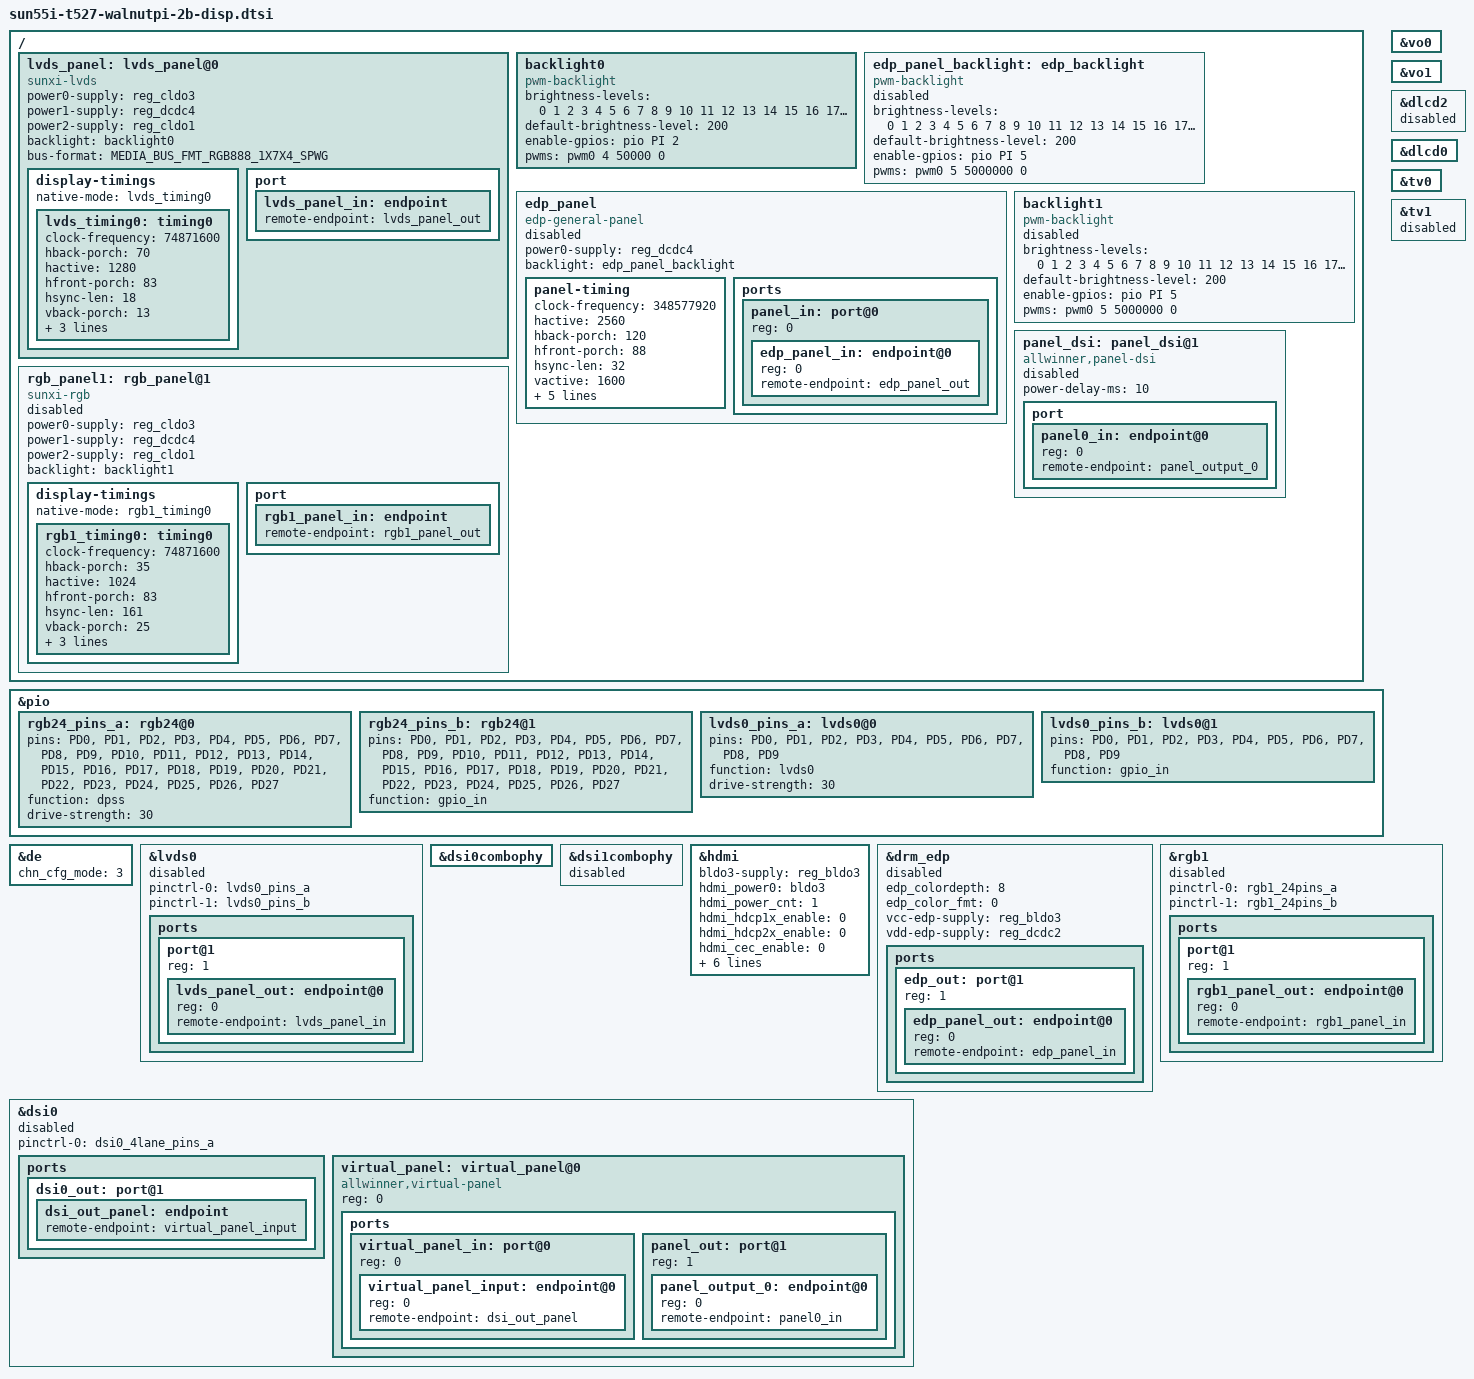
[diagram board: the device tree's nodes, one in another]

&pio {
	
	rgb24_pins_a: rgb24@0 {
		pins = "PD0", "PD1", "PD2", "PD3", "PD4", "PD5", "PD6", "PD7", "PD8", "PD9", \
		"PD10", "PD11", "PD12", "PD13", "PD14", "PD15", "PD16", "PD17", "PD18", "PD19", \
		"PD20", "PD21", "PD22","PD23","PD24","PD25","PD26","PD27";
		function = "dpss";
		drive-strength = <30>;
	};
	
	rgb24_pins_b: rgb24@1 {
		pins = "PD0", "PD1", "PD2", "PD3", "PD4", "PD5", "PD6", "PD7", "PD8", "PD9", \
		"PD10", "PD11", "PD12", "PD13", "PD14", "PD15", "PD16", "PD17", "PD18", "PD19", \
		"PD20", "PD21", "PD22", "PD23","PD24","PD25","PD26","PD27";
		function = "gpio_in";
	};
	
	lvds0_pins_a: lvds0@0 {
		pins = "PD0", "PD1", "PD2", "PD3", "PD4", "PD5", "PD6", "PD7", "PD8", "PD9";
		function = "lvds0";
		drive-strength = <30>;
	};
	
	lvds0_pins_b: lvds0@1 {
		pins = "PD0", "PD1", "PD2", "PD3", "PD4", "PD5", "PD6", "PD7", "PD8", "PD9";
		function = "gpio_in";
	};
};


&de {
	chn_cfg_mode = <3>;
	status = "okay";
};

&vo0 {
	status = "okay";
};

&vo1 {
	status = "okay";
};



&dlcd2 {
	status = "disabled";
};


/ {
	lvds_panel: lvds_panel@0 {
		compatible = "sunxi-lvds";
		status = "okay";
		power0-supply = <&reg_cldo3>;
		power1-supply = <&reg_dcdc4>;
		power2-supply = <&reg_cldo1>;
		backlight = <&backlight0>;
		bus-format = <MEDIA_BUS_FMT_RGB888_1X7X4_SPWG>;
		display-timings {
			native-mode = <&lvds_timing0>;
			lvds_timing0: timing0 {
				clock-frequency = <74871600>;
				hback-porch = <70>;
				hactive = <1280>;
				hfront-porch = <83>;
				hsync-len = <18>;
				vback-porch = <13>;
				vactive = <800>;
				vfront-porch = <37>;
				vsync-len = <10>;
			};
		};
		port {
			lvds_panel_in: endpoint {
				remote-endpoint = <&lvds_panel_out>;
			};
		};
	};
	backlight0: backlight0 {
		compatible = "pwm-backlight";
		status = "okay";
		brightness-levels = <
		0   1   2   3   4   5   6   7
		8   9  10  11  12  13  14  15
		16  17  18  19  20  21  22  23
		24  25  26  27  28  29  30  31
		32  33  34  35  36  37  38  39
		40  41  42  43  44  45  46  47
		48  49  50  51  52  53  54  55
		56  57  58  59  60  61  62  63
		64  65  66  67  68  69  70  71
		72  73  74  75  76  77  78  79
		80  81  82  83  84  85  86  87
		88  89  90  91  92  93  94  95
		96  97  98  99 100 101 102 103
		104 105 106 107 108 109 110 111
		112 113 114 115 116 117 118 119
		120 121 122 123 124 125 126 127
		128 129 130 131 132 133 134 135
		136 137 138 139 140 141 142 143
		144 145 146 147 148 149 150 151
		152 153 154 155 156 157 158 159
		160 161 162 163 164 165 166 167
		168 169 170 171 172 173 174 175
		176 177 178 179 180 181 182 183
		184 185 186 187 188 189 190 191
		192 193 194 195 196 197 198 199
		200 201 202 203 204 205 206 207
		208 209 210 211 212 213 214 215
		216 217 218 219 220 221 222 223
		224 225 226 227 228 229 230 231
		232 233 234 235 236 237 238 239
		240 241 242 243 244 245 246 247
		248 249 250 251 252 253 254 255>;
		default-brightness-level = <200>;
		enable-gpios = <&pio PI 2 GPIO_ACTIVE_HIGH>;
		pwms = <&pwm0 4 50000 0>;
	};
};
&lvds0 {
	status = "disabled";
	//	dual-channel = <0>;
	pinctrl-0 = <&lvds0_pins_a>;
	pinctrl-1 = <&lvds0_pins_b>;
	pinctrl-names = "active","sleep";
	ports {
		port@1 {
			reg = <1>;
			#address-cells = <1>;
			#size-cells = <0>;
			lvds_panel_out: endpoint@0 {
				reg = <0>;
				remote-endpoint = <&lvds_panel_in>;
			};
		};
	};
};
&dlcd0 {
	status = "okay";
};

&dsi0combophy {
	status = "okay";
};

&dsi1combophy {
	status = "disabled";
};


&tv0 {
	status = "okay";
};



&hdmi {
	bldo3-supply = <&reg_bldo3>;
	hdmi_power0 = "bldo3";
	hdmi_power_cnt = <1>;
	
	hdmi_hdcp1x_enable = <0>;
	hdmi_hdcp2x_enable = <0>;
	hdmi_cec_enable = <0>;
	
	inno_phy0 = <
		 25200 160000 0x00020202 0x1c1c1c1c 0x00000000 0x00000000
		160000 300000 0x02060708 0x1c1c1c1c 0x00000000 0x03030300
		300000 600000 0x020f0f0f 0x1c1c1c1c 0x00000000 0x03030300>;
	inno_phy1 = <
		 25200 160000 0x01000102 0x1c1c1c1c 0x00000000 0x02020200
		160000 300000 0x0a020202 0x14142B14 0x00000000 0x03030300
		300000 600000 0x010f0f0f 0x1c1c1c1c 0x00000000 0x00000000>;
	inno_phy2 = <
		 25200 190000 0x01010102 0x1c1c1c1c 0x00000000 0x00000000
		190000 300000 0x01020304 0x1c1c1c1c 0x00000000 0x05050500
		300000 600000 0x010e0f0f 0x1c1c1c1c 0x00000000 0x00000000>;
	
	status = "okay";
};


&tv1 {
	status = "disabled";
};
&drm_edp {
	status = "disabled";
	
	edp_colordepth = <8>; /* 6/8/10/12/16 */
	edp_color_fmt = <0>; /* 0:RGB  1: YUV444  2: YUV422 */
	
	vcc-edp-supply = <&reg_bldo3>;
	vdd-edp-supply = <&reg_dcdc2>;
	ports {
		edp_out: port@1 {
			#address-cells = <1>;
			#size-cells = <0>;
			reg = <1>;
			edp_panel_out: endpoint@0 {
				reg = <0>;
				remote-endpoint = <&edp_panel_in>;
			};
		};
	};
};
/{
	
	edp_panel_backlight: edp_backlight {
		compatible = "pwm-backlight";
		status = "disabled";
		brightness-levels = <
		0   1   2   3   4   5   6   7
		8   9  10  11  12  13  14  15
		16  17  18  19  20  21  22  23
		24  25  26  27  28  29  30  31
		32  33  34  35  36  37  38  39
		40  41  42  43  44  45  46  47
		48  49  50  51  52  53  54  55
		56  57  58  59  60  61  62  63
		64  65  66  67  68  69  70  71
		72  73  74  75  76  77  78  79
		80  81  82  83  84  85  86  87
		88  89  90  91  92  93  94  95
		96  97  98  99 100 101 102 103
		104 105 106 107 108 109 110 111
		112 113 114 115 116 117 118 119
		120 121 122 123 124 125 126 127
		128 129 130 131 132 133 134 135
		136 137 138 139 140 141 142 143
		144 145 146 147 148 149 150 151
		152 153 154 155 156 157 158 159
		160 161 162 163 164 165 166 167
		168 169 170 171 172 173 174 175
		176 177 178 179 180 181 182 183
		184 185 186 187 188 189 190 191
		192 193 194 195 196 197 198 199
		200 201 202 203 204 205 206 207
		208 209 210 211 212 213 214 215
		216 217 218 219 220 221 222 223
		224 225 226 227 228 229 230 231
		232 233 234 235 236 237 238 239
		240 241 242 243 244 245 246 247
		248 249 250 251 252 253 254 255>;
		default-brightness-level = <200>;
		enable-gpios = <&pio PI 5 GPIO_ACTIVE_HIGH>;
		/* power-supply = <&reg_backlight_12v>; */
		pwms = <&pwm0 5 5000000 0>;
	};
	
	edp_panel: edp_panel {
		compatible = "edp-general-panel";
		status = "disabled";
		power0-supply = <&reg_dcdc4>;
		
		backlight = <&edp_panel_backlight>;
		
		panel-timing {
			clock-frequency = <348577920>; /* pixel clock */
			hactive = <2560>;
			hback-porch = <120>;
			hfront-porch = <88>;
			hsync-len = <32>;
			vactive = <1600>;
			vback-porch = <71>;
			vfront-porch = <28>;
			vsync-len = <5>;
			/* hor_sync_polarity */
			hsync-active = <1>;
			/* ver_sync_polarity */
			vsync-active = <1>;
		};
		ports {
			#address-cells = <1>;
			#size-cells = <0>;
			panel_in: port@0 {
				#address-cells = <1>;
				#size-cells = <0>;
				reg = <0>;
				edp_panel_in: endpoint@0 {
					reg = <0>;
					remote-endpoint = <&edp_panel_out>;
				};
			};
		};
	};
	
};


&rgb1 {
	status = "disabled";
	pinctrl-0 = <&rgb1_24pins_a>;
	pinctrl-1 = <&rgb1_24pins_b>;
	pinctrl-names = "active","sleep";
	ports {
		port@1 {
			reg = <1>;
			#address-cells = <1>;
			#size-cells = <0>;
			rgb1_panel_out: endpoint@0 {
				reg = <0>;
				remote-endpoint = <&rgb1_panel_in>;
			};
		};
	};
};
/{
	rgb_panel1: rgb_panel@1 {
		compatible = "sunxi-rgb";
		status = "disabled";
		power0-supply = <&reg_cldo3>;
		power1-supply = <&reg_dcdc4>;
		power2-supply = <&reg_cldo1>;
		
		backlight = <&backlight1>;
		#address-cells = <1>;
		#size-cells = <0>;
		display-timings {
			native-mode = <&rgb1_timing0>;
			
			rgb1_timing0: timing0 {
				clock-frequency = <74871600>;
				hback-porch = <35>;
				hactive = <1024>;
				hfront-porch = <83>;
				hsync-len = <161>;
				vback-porch = <25>;
				vactive = <600>;
				vfront-porch = <15>;
				vsync-len = <10>;
			};
		};
		port {
			rgb1_panel_in: endpoint {
				remote-endpoint = <&rgb1_panel_out>;
			};
		};
	};
	backlight1: backlight1 {
		compatible = "pwm-backlight";
		status = "disabled";
		brightness-levels = <
		0   1   2   3   4   5   6   7
		8   9  10  11  12  13  14  15
		16  17  18  19  20  21  22  23
		24  25  26  27  28  29  30  31
		32  33  34  35  36  37  38  39
		40  41  42  43  44  45  46  47
		48  49  50  51  52  53  54  55
		56  57  58  59  60  61  62  63
		64  65  66  67  68  69  70  71
		72  73  74  75  76  77  78  79
		80  81  82  83  84  85  86  87
		88  89  90  91  92  93  94  95
		96  97  98  99 100 101 102 103
		104 105 106 107 108 109 110 111
		112 113 114 115 116 117 118 119
		120 121 122 123 124 125 126 127
		128 129 130 131 132 133 134 135
		136 137 138 139 140 141 142 143
		144 145 146 147 148 149 150 151
		152 153 154 155 156 157 158 159
		160 161 162 163 164 165 166 167
		168 169 170 171 172 173 174 175
		176 177 178 179 180 181 182 183
		184 185 186 187 188 189 190 191
		192 193 194 195 196 197 198 199
		200 201 202 203 204 205 206 207
		208 209 210 211 212 213 214 215
		216 217 218 219 220 221 222 223
		224 225 226 227 228 229 230 231
		232 233 234 235 236 237 238 239
		240 241 242 243 244 245 246 247
		248 249 250 251 252 253 254 255>;
		default-brightness-level = <200>;
		enable-gpios = <&pio PI 5 GPIO_ACTIVE_HIGH>;
		pwms = <&pwm0 5 5000000 0>;
	};
};

/{
	panel_dsi: panel_dsi@1 {
		compatible = "allwinner,panel-dsi";
		status = "disabled";
		power-delay-ms = <10>;
		
		port {
			#address-cells = <1>;
			#size-cells = <0>;
			panel0_in: endpoint@0 {
				reg = <0>;
				remote-endpoint = <&panel_output_0>;
			};
		};
		
	};
};
&dsi0{
	#address-cells = <1>;
	#size-cells = <0>;
	status = "disabled";
	pinctrl-0 = <&dsi0_4lane_pins_a>;
	pinctrl-names = "active";
	ports {
		dsi0_out: port@1{
			dsi_out_panel: endpoint {
				remote-endpoint = <&virtual_panel_input>;
			};
		};
	};
	virtual_panel: virtual_panel@0 {
		compatible = "allwinner,virtual-panel";
		status = "okay";
		reg = <0>;
		ports {
			#address-cells = <1>;
			#size-cells = <0>;
			virtual_panel_in: port@0 {
				reg = <0>;
				#address-cells = <1>;
				#size-cells = <0>;
				virtual_panel_input: endpoint@0 {
					reg = <0>;
					remote-endpoint = <&dsi_out_panel>;
				};
			};
			panel_out: port@1 {
				reg = <1>;
				#address-cells = <1>;
				#size-cells = <0>;
				panel_output_0: endpoint@0 {
					reg = <0>;
					remote-endpoint = <&panel0_in>;
				};
			};
		};
	};
};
